# LPC54005 register map
Vendor: nxp.com; File version: 1.0
CPU: CM4 r0p1, little endian, MPU, FPU, VTOR, 3 interrupt priority bits
Registers are 32-bit, read-write, reset 0x0 unless marked. A register's access mark holds for its fields unless they carry their own. Offsets are from the block's base; [hi:lo] are bit positions; {n}, {i} and the like mark numbered series; 'fields as' and 'values as' point back to an identical list.

## SYSCON — LPC5460x System configuration (SYSCON)
Base 0x40000000
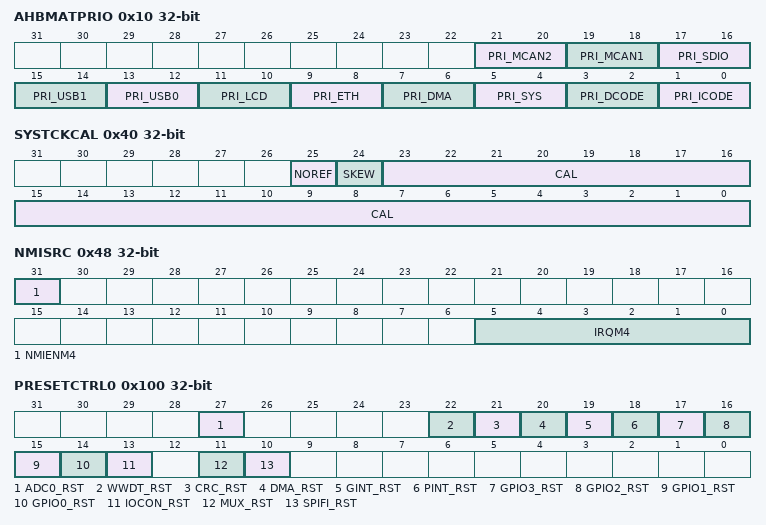
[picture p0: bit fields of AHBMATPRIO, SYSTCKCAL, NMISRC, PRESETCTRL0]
0x10 AHBMATPRIO — AHB multilayer matrix priority control
  [21:20] PRI_MCAN2 — MCAN2 priority.
  [19:18] PRI_MCAN1 — MCAN1 priority.
  [17:16] PRI_SDIO — SDIO priority.
  [15:14] PRI_USB1 — USB1 DMA priority.
  [13:12] PRI_USB0 — USB0 DMA priority.
  [11:10] PRI_LCD — LCD DMA priority.
  [9:8] PRI_ETH — Ethernet DMA priority.
  [7:6] PRI_DMA — DMA controller priority.
  [5:4] PRI_SYS — System bus priority.
  [3:2] PRI_DCODE — D-Code bus priority.
  [1:0] PRI_ICODE — I-Code bus priority.
0x40 SYSTCKCAL — System tick counter calibration
  [25] NOREF — Initial value for the Systick timer.
  [24] SKEW — Initial value for the Systick timer.
  [23:0] CAL — System tick timer calibration value.
0x48 NMISRC — NMI Source Select
  [31] NMIENM4 — Write a 1 to this bit to enable the Non-Maskable Interrupt (NMI) source selected by IRQM4.
  [5:0] IRQM4 — The IRQ number of the interrupt that acts as the Non-Maskable Interrupt (NMI) for the Cortex-M4, if enabled by NMIENM4.
0x4C ASYNCAPBCTRL reset 0x1 — Asynchronous APB Control
  [0] ENABLE — Enables the asynchronous APB bridge and subsystem.
    0=DISABLED (Disabled. Asynchronous APB bridge is disabled.); 1=ENABLED (Enabled. Asynchronous APB bridge is enabled.)
{0xC0+4i} PIOPORCAP[{i}] (i=0..1) ro — POR captured value of port n
  [31:0] PIOPORCAP — State of PIOn_31 through PIOn_0 at power-on reset
{0xD0+4i} PIORESCAP[{i}] (i=0..1) ro — Reset captured value of port n
  [31:0] PIORESCAP — State of PIOn_31 through PIOn_0 for resets other than POR.
0x100 PRESETCTRL0 — Peripheral reset control n
  [27] ADC0_RST — ADC0 reset control. 0 = Clear reset to this function. 1 = Assert reset to this function.
  [22] WWDT_RST — Watchdog timer reset control. 0 = Clear reset to this function. 1 = Assert reset to this function.
  [21] CRC_RST — CRC generator reset control. 0 = Clear reset to this function. 1 = Assert reset to this function.
  [20] DMA_RST — DMA reset control. 0 = Clear reset to this function. 1 = Assert reset to this function.
  [19] GINT_RST — Grouped interrupt (GINT) reset control. 0 = Clear reset to this function. 1 = Assert reset to this function.
  [18] PINT_RST — Pin interrupt (PINT) reset control. 0 = Clear reset to this function. 1 = Assert reset to this function.
  [17] GPIO3_RST — GPIO3 reset control.
  [16] GPIO2_RST — GPIO2 reset control.
  [15] GPIO1_RST — GPIO1 reset control. 0 = Clear reset to this function. 1 = Assert reset to this function.
  [14] GPIO0_RST — GPIO0 reset control. 0 = Clear reset to this function. 1 = Assert reset to this function.
  [13] IOCON_RST — IOCON reset control. 0 = Clear reset to this function. 1 = Assert reset to this function.
  [11] MUX_RST — Input mux reset control. 0 = Clear reset to this function. 1 = Assert reset to this function.
  [10] SPIFI_RST — SPIFI reset control.
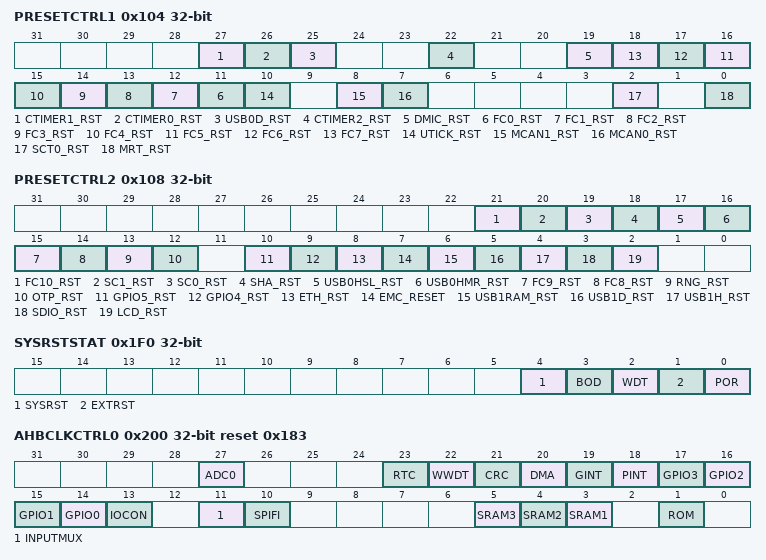
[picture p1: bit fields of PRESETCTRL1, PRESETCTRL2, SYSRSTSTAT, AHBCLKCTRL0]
0x104 PRESETCTRL1 — Peripheral reset control n
  [27] CTIMER1_RST — CTIMER1 reset control. 0 = Clear reset to this function. 1 = Assert reset to this function.
  [26] CTIMER0_RST — CTIMER0 reset control. 0 = Clear reset to this function. 1 = Assert reset to this function.
  [25] USB0D_RST — USB0 reset control. 0 = Clear reset to this function. 1 = Assert reset to this function.
  [22] CTIMER2_RST — CTIMER2 reset control. 0 = Clear reset to this function. 1 = Assert reset to this function
  [19] DMIC_RST — Digital microphone interface reset control. 0 = Clear reset to this function. 1 = Assert reset to this function.
  [n+11] FC{n}_RST (n=0..7) — Flexcomm {n} reset control. 0 = Clear reset to this function. 1 = Assert reset to this function.
  [10] UTICK_RST — Micro-tick Timer reset control. 0 = Clear reset to this function. 1 = Assert reset to this function.
  [8] MCAN1_RST — 0 = Clear reset to this function.
  [7] MCAN0_RST — 0 = Clear reset to this function.
  [2] SCT0_RST — State configurable timer 0 (SCT0) reset control. 0 = Clear reset to this function. 1 = Assert reset to this function.
  [0] MRT_RST — Multi-rate timer (MRT) reset control. 0 = Clear reset to this function. 1 = Assert reset to this function.
0x108 PRESETCTRL2 (reset mask 0xE4FFD85) — Peripheral reset control n
  [21] FC10_RST — Flexcomm 10 reset control.
  [20] SC1_RST — Smart card 1 reset control.
  [19] SC0_RST — Smart card 0 reset control.
  [18] SHA_RST — SHA reset control.
  [17] USB0HSL_RST — USB0 HOST slave reset control.
  [16] USB0HMR_RST — USB0 HOST master reset control.
  [15] FC9_RST — Flexcomm 9 reset control.
  [14] FC8_RST — Flexcomm 8 reset control.
  [13] RNG_RST — RNG reset control.
  [12] OTP_RST — OTP reset control.
  [10] GPIO5_RST — GPIO5 reset control.
  [9] GPIO4_RST — GPIO4 reset control.
  [8] ETH_RST — Ethernet reset control.
  [7] EMC_RESET — EMC reset control.
  [6] USB1RAM_RST — USB1 RAM reset control.
  [5] USB1D_RST — USB1 Device reset control.
  [4] USB1H_RST — USB1 Host reset control.
  [3] SDIO_RST — SDIO reset control.
  [2] LCD_RST — LCD reset control.
{0x120+4i} PRESETCTRLSET[{i}] (i=0..2) wo — Set bits in PRESETCTRLn
  [31:0] RST_SET — Writing ones to this register sets the corresponding bit or bits in the PRESETCTRLn register, if they are implemented. Bits that do not correspond to defined bits in PRESETCTRLn are reserved and only zeroes should be written to them.
{0x140+4i} PRESETCTRLCLR[{i}] (i=0..2) wo — Clear bits in PRESETCTRLn
  [31:0] RST_CLR — Writing ones to this register clears the corresponding bit or bits in the PRESETCTRLn register, if they are implemented. Bits that do not correspond to defined bits in PRESETCTRLn are reserved and only zeroes should be written to them.
0x1F0 SYSRSTSTAT — System reset status register
  [4] SYSRST — Status of the software system reset
    0=NO_SYSTEM_RESET_DETECTED; 1=SYSTEM_RESET_DETECTED (System reset detected. Writing a one clears this reset.)
  [3] BOD — Status of the Brown-out detect reset
    0=NO_BOD_RESET_DETECTED; 1=BOD_RESET_DETECTED (BOD reset detected. Writing a one clears this reset.)
  [2] WDT — Status of the Watchdog reset
    0=NO_WDT_RESET_DETECTED; 1=WDT_RESET_DETECTED (WDT reset detected. Writing a one clears this reset.)
  [1] EXTRST — Status of the external RESET pin. External reset status
    0=NO_RESET_DETECTED (No reset event detected.); 1=RESET_DETECTED (Reset detected. Writing a one clears this reset.)
  [0] POR — POR reset status
    0=NO_POR_DETECTED; 1=POR_DETECTED (POR detected. Writing a one clears this reset.)
0x200 AHBCLKCTRL0 reset 0x183 — AHB Clock control n
  [27] ADC0 — Enables the clock for the ADC0 register interface.
  [23] RTC — Enables the bus clock for the RTC. 0 = Disable; 1 = Enable.
  [22] WWDT — Enables the clock for the Watchdog Timer. 0 = Disable; 1 = Enable.
  [21] CRC — Enables the clock for the CRC engine. 0 = Disable; 1 = Enable.
  [20] DMA — Enables the clock for the DMA controller. 0 = Disable; 1 = Enable.
  [19] GINT — Enables the clock for the grouped pin interrupt block. 0 = Disable; 1 = Enable.
  [18] PINT — Enables the clock for the pin interrupt block.0 = Disable; 1 = Enable.
  [17] GPIO3 — Enables the clock for the GPIO3 port registers.
  [16] GPIO2 — Enables the clock for the GPIO2 port registers.
  [15] GPIO1 — Enables the clock for the GPIO1 port registers. 0 = Disable; 1 = Enable.
  [14] GPIO0 — Enables the clock for the GPIO0 port registers. 0 = Disable; 1 = Enable.
  [13] IOCON — Enables the clock for the IOCON block. 0 = Disable; 1 = Enable.
  [11] INPUTMUX — Enables the clock for the input muxes. 0 = Disable; 1 = Enable.
  [10] SPIFI — Enables the clock for the SPIFI. 0 = Disable; 1 = Enable.
  [5] SRAM3 — Enables the clock for SRAM3.
  [4] SRAM2 — Enables the clock for SRAM2. 0 = Disable; 1 = Enable.
  [3] SRAM1 — Enables the clock for SRAM1. 0 = Disable; 1 = Enable.
  [1] ROM — Enables the clock for the Boot ROM. 0 = Disable; 1 = Enable.
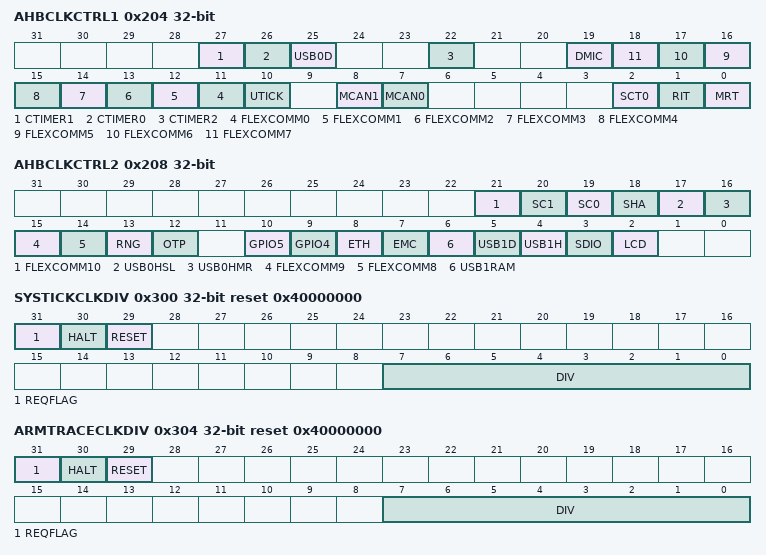
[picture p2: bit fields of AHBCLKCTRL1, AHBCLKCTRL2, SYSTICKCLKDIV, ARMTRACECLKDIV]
0x204 AHBCLKCTRL1 — AHB Clock control n
  [27] CTIMER1 — Enables the clock for timer CTIMER1. 0 = Disable; 1 = Enable.
  [26] CTIMER0 — Enables the clock for timer CTIMER0. 0 = Disable; 1 = Enable.
  [25] USB0D — Enables the clock for the USB0 device interface. 0 = Disable; 1 = Enable.
  [22] CTIMER2 — Enables the clock for CTIMER 2. 0 = Disable; 1 = Enable.
  [19] DMIC — Enables the clock for the digital microphone interface. 0 = Disable; 1 = Enable.
  [n+11] FLEXCOMM{n} (n=0..7) — Enables the clock for Flexcomm {n}. 0 = Disable; 1 = Enable.
  [10] UTICK — Enables the clock for the Micro-tick Timer. 0 = Disable; 1 = Enable.
  [8] MCAN1 — Enables the clock for MCAN1.
  [7] MCAN0 — Enables the clock for MCAN0.
  [2] SCT0 — Enables the clock for SCT0.
  [1] RIT — Enables the clock for the Repetitive Interrupt Timer.
  [0] MRT — Enables the clock for the Multi-Rate Timer.
0x208 AHBCLKCTRL2 (reset mask 0xE4FFD87) — AHB Clock control n
  [21] FLEXCOMM10 — Enables the clock for the Flexcomm10 interface.
  [20] SC1 — Enables the clock for the Smart card1 interface.
  [19] SC0 — Enables the clock for the Smart card0 interface.
  [18] SHA — Enables the clock for the SHA interface.
  [17] USB0HSL — Enables the clock for the USB host slave interface.
  [16] USB0HMR — Enables the clock for the USB host master interface.
  [15] FLEXCOMM9 — Enables the clock for the Flexcomm9 interface.
  [14] FLEXCOMM8 — Enables the clock for the Flexcomm8 interface.
  [13] RNG — Enables the clock for the RNG interface.
  [12] OTP — Enables the clock for the OTP interface.
  [10] GPIO5 — Enables the clock for the GPIO5 interface.
  [9] GPIO4 — Enables the clock for the GPIO4 interface.
  [8] ETH — Enables the clock for the ethernet interface.
  [7] EMC — Enables the clock for the EMC interface.
  [6] USB1RAM — Enables the clock for the USB1 RAM interface.
  [5] USB1D — Enables the clock for the USB1 device interface.
  [4] USB1H — Enables the clock for the USB1 host interface.
  [3] SDIO — Enables the clock for the SDIO interface.
  [2] LCD — Enables the clock for the LCD interface.
{0x220+4i} AHBCLKCTRLSET[{i}] (i=0..2) wo — Set bits in AHBCLKCTRLn
  [31:0] CLK_SET — Writing ones to this register sets the corresponding bit or bits in the AHBCLKCTRLn register, if they are implemented. Bits that do not correspond to defined bits in AHBCLKCTRLn are reserved and only zeroes should be written to them.
{0x240+4i} AHBCLKCTRLCLR[{i}] (i=0..2) wo — Clear bits in AHBCLKCTRLn
  [31:0] CLK_CLR — Writing ones to this register clears the corresponding bit or bits in the AHBCLKCTRLn register, if they are implemented. Bits that do not correspond to defined bits in AHBCLKCTRLn are reserved and only zeroes should be written to them.
0x27C STICKCLKSEL — Systick timer clock source selection
  [2:0] SEL
    0=MAIN_CLOCK (Main clock (main_clk)); 1=WATCHDOG_OSCILLATOR (Watchdog oscillator (wdt_clk)); 2=RTC_OSC_OUTPUT (RTC oscillator 32 kHz output (32k_clk)); 3=FRO_12_MHZ (FRO 12 MHz (fro_12m)); 7=NONE (None, this may be selected to reduce power when no output is needed.)
0x280 MAINCLKSELA — Main clock source select A
  [1:0] SEL — Clock source for main clock source selector A
    0=FRO_12_MHZ (FRO 12 MHz (fro_12m)); 1=CLKIN (CLKIN (clk_in)); 2=WATCHDOG_OSCILLATOR (Watchdog oscillator (wdt_clk)); 3=FRO_HF (FRO 96 or 48 MHz (fro_hf))
0x284 MAINCLKSELB — Main clock source select B
  [1:0] SEL — Clock source for main clock source selector B. Selects the clock source for the main clock.
    0=MAINCLKSELA (MAINCLKSELA. Use the clock source selected in MAINCLKSELA register.); 2=SYSTEM_PLL_OUTPUT (System PLL output (pll_clk)); 3=RTC_OSC_OUTPUT (RTC oscillator 32 kHz output (32k_clk))
0x288 CLKOUTSELA reset 0x7 — CLKOUT clock source select A
  [2:0] SEL — CLKOUT clock source selection
    0=MAIN_CLOCK (Main clock (main_clk)); 1=CLKIN (CLKIN (clk_in)); 2=WATCHDOG_OSCILLATOR (Watchdog oscillator (wdt_clk)); 3=FRO_HF (FRO 96 or 48 MHz (fro_hf)); 4=SYSTEM_PLL_OUTPUT (PLL output (pll_clk)); 5=USB_PLL_CLOCK (USB PLL clock (usb_pll_clk)); 6=AUDIO_PLL_OUTPUT (Audio PLL clock (audio_pll_clk)); 7=RTC_OSC_OUTPUT (RTC oscillator 32 kHz output (32k_clk))
0x290 SYSPLLCLKSEL — PLL clock source select
  [2:0] SEL — System PLL clock source selection.
    0=FRO_12_MHZ (FRO 12 MHz (fro_12m)); 1=CLKIN (CLKIN (clk_in)); 3=RTC_OSC_OUTPUT (RTC oscillator 32 kHz output (32k_clk)); 7=NONE (None, this may be selected in order to reduce power when no output is needed.)
0x298 AUDPLLCLKSEL — Audio PLL clock source select
  [2:0] SEL — Audio PLL clock source selection.
    0=FRO_12_MHZ (FRO 12 MHz (fro_12m)); 1=CLKIN (CLKIN (clk_in)); 7=NONE (None, this may be selected in order to reduce power when no output is needed.)
0x2A0 SPIFICLKSEL reset 0x7 — SPIFI clock source select
  [2:0] SEL — System PLL clock source selection
    0=MAIN_CLOCK (Main clock (main_clk)); 1=SYSTEM_PLL_OUTPUT (System PLL output (pll_clk)); 2=USB_PLL_OUTPUT (USB PLL clock (usb_pll_clk)); 3=FRO_HF (FRO 96 or 48 MHz (fro_hf)); 4=AUDIO_PLL_OUTPUT (Audio PLL clock (audio_pll_clk)); 7=NONE (None, this may be selected in order to reduce power when no output is needed.)
0x2A4 ADCCLKSEL reset 0x7 — ADC clock source select
  [2:0] SEL — ADC clock source selection
    0=FRO_HF (FRO 96 or 48 MHz (fro_hf)); 1=SYSTEM_PLL_OUTPUT (System PLL output (pll_clk)); 2=USB_PLL_CLOCK (USB PLL clock (usb_pll_clk)); 3=AUDIO_PLL_CLOCK (Audio PLL clock (audio_pll_clk)); 7=NONE (None, this may be selected in order to reduce power when no output is needed.)
0x2A8 USB0CLKSEL reset 0x7 — USB0 clock source select
  [2:0] SEL — USB0 device clock source selection.
    0=FRO_HF (FRO 96 or 48 MHz (fro_hf)); 1=SYSTEM_PLL_OUTPUT (System PLL output (pll_clk)); 2=USB_PLL_CLOCK (USB PLL clock (usb_pll_clk)); 7=NONE (None, this may be selected in order to reduce power when no output is needed.)
0x2AC USB1CLKSEL reset 0x7 — USB1 clock source select
  [2:0] SEL — USB1 PHY clock source selection.
    0=MAIN_CLOCK (Main clock (main_clk)); 1=SYSTEM_PLL_OUTPUT (System PLL output (pll_clk)); 2=USB_PLL_CLOCK (USB PLL clock (usb_pll_clk)); 7=NONE (None, this may be selected in order to reduce power when no output is needed.)
{0x2B0+4i} FCLKSEL[{i}] (i=0..9) reset 0x7 — Flexcomm clock source select
  [2:0] SEL — Flexcomm clock source selection. One per Flexcomm.
    0=FRO_12_MHZ (FRO 12 MHz (fro_12m)); 1=FRO_HF_DIV (FRO HF DIV (fro_hf_div)); 2=AUDIO_PLL_OUTPUT (Audio PLL clock (audio_pll_clk)); 3=MCLK_INPUT (MCLK pin input, when selected in IOCON (mclk_in)); 4=FRG_CLOCK_OUTPUT (FRG clock, the output of the fractional rate generator (frg_clk)); 7=NONE (None, this may be selected in order to reduce power when no output is needed.)
0x2D8 FCLKSEL10 reset 0x7 — Flexcomm 10 clock source select
  [2:0] SEL — Flexcomm clock source selection. One per Flexcomm.
    0=MAIN_CLOCK (Main clock (main_clk)); 1=SYSTEM_PLL_OUTPUT (System PLL output (pll_clk)); 2=USB_PLL_CLOCK (USB PLL clock (usb_pll_clk)); 3=FRO_HF (FRO 96 or 48 MHz (fro_hf)); 4=AUDIO_PLL_OUTPUT (Audio PLL clock (audio_pll_clk)); 7=NONE (None, this may be selected in order to reduce power when no output is needed.)
0x2E0 MCLKCLKSEL reset 0x7 — MCLK clock source select
  [2:0] SEL — MCLK source select. This may be used by Flexcomms that support I2S, and/or by the digital microphone subsystem.
    0=FRO_HF_DIV (FRO HF DIV (fro_hf_div)); 1=AUDIO_PLL_OUTPUT (Audio PLL clock (audio_pll_clk)); 7=NONE (None, this may be selected in order to reduce power when no output is needed.)
0x2E8 FRGCLKSEL reset 0x7 — Fractional Rate Generator clock source select
  [2:0] SEL — Fractional Rate Generator clock source select.
    0=MAIN_CLOCK (Main clock (main_clk)); 1=SYSTEM_PLL_OUTPUT (System PLL output (pll_clk)); 2=FRO_12_MHZ (FRO 12 MHz (fro_12m)); 3=FRO_HF (FRO 96 or 48 MHz (fro_hf)); 7=NONE (None, this may be selected in order to reduce power when no output is needed.)
0x2EC DMICCLKSEL reset 0x7 — Digital microphone (DMIC) subsystem clock select
  [2:0] SEL — DMIC (audio subsystem) clock source select.
    0=FRO_12_MHZ (FRO 12 MHz (fro_12m)); 1=FRO_HF_DIV (FRO HF DIV (fro_hf_div)); 2=AUDIO_PLL_OUTPUT (Audio PLL clock (audio_pll_clk)); 3=MCLK_INPUT (MCLK pin input, when selected in IOCON (mclk_in)); 4=MAIN_CLOCK (Main clock (main_clk)); 5=WATCHDOG_OSCILLATOR (Watchdog oscillator (wdt_clk)); 7=NONE (None, this may be selected in order to reduce power when no output is needed.)
0x2F0 SCTCLKSEL reset 0x7 — SCTimer/PWM clock source select
  [2:0] SEL — SCT clock source select.
    0=MAIN_CLOCK (Main clock (main_clk)); 1=SYSTEM_PLL_OUTPUT (System PLL output (pll_clk)); 2=FRO_HF (FRO 96 or 48 MHz (fro_hf)); 3=AUDIO_PLL_OUTPUT (Audio PLL clock (audio_pll_clk)); 7=NONE (None, this may be selected in order to reduce power when no output is needed.)
0x2F4 LCDCLKSEL reset 0x3 — LCD clock source select
  [1:0] SEL — LCD clock source select.
    0=MAIN_CLOCK (Main clock (main_clk)); 1=LCDCLKIN (LCDCLKIN (LCDCLK_EXT)); 2=FRO_HF (FRO 96 or 48 MHz (fro_hf)); 3=NONE (None, this may be selected in order to reduce power when no output is needed.)
0x2F8 SDIOCLKSEL reset 0x7 — SDIO clock source select
  [2:0] SEL — SDIO clock source select.
    values as FCLKSEL10.SEL
0x300 SYSTICKCLKDIV reset 0x40000000 — SYSTICK clock divider
  [31] REQFLAG — Divider status flag.
  [30] HALT — Halts the divider counter.
  [29] RESET — Resets the divider counter. Can be used to make sure a new divider value is used right away rather than completing the previous count.
  [7:0] DIV — Clock divider value. 0: Divide by 1 up to 255: Divide by 256.
0x304 ARMTRACECLKDIV reset 0x40000000 — ARM Trace clock divider
  [31] REQFLAG — Divider status flag.
  [30] HALT — Halts the divider counter.
  [29] RESET — Resets the divider counter.
  [7:0] DIV — Clock divider value.
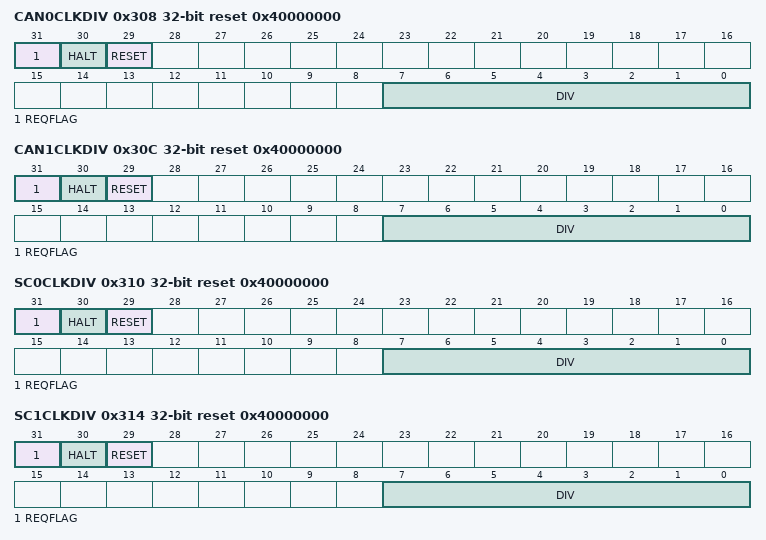
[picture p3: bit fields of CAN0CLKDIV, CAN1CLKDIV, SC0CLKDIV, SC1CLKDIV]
0x308 CAN0CLKDIV reset 0x40000000 — MCAN0 clock divider
  fields as ARMTRACECLKDIV
0x30C CAN1CLKDIV reset 0x40000000 — MCAN1 clock divider
  fields as SYSTICKCLKDIV
0x310 SC0CLKDIV reset 0x40000000 — Smartcard0 clock divider
  fields as ARMTRACECLKDIV
0x314 SC1CLKDIV reset 0x40000000 — Smartcard1 clock divider
  fields as ARMTRACECLKDIV
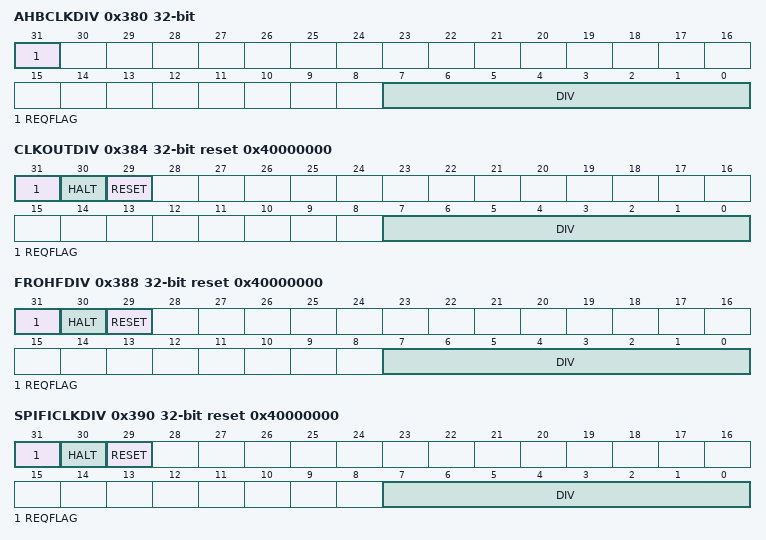
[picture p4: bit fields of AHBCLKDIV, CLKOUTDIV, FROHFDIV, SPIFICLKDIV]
0x380 AHBCLKDIV (reset mask 0x600000FF) — AHB clock divider
  [31] REQFLAG — Divider status flag.
  [7:0] DIV — Clock divider value. 0: Divide by 1 up to 255: Divide by 256.
0x384 CLKOUTDIV reset 0x40000000 (reset mask 0x600000FF) — CLKOUT clock divider
  [31] REQFLAG — Divider status flag.
  [30] HALT — Halts the divider counter. The intent is to allow the divider clock source to be changed without the risk of a glitch at the output.
  [29] RESET — Resets the divider counter. Can be used to make sure a new divider value is used right away rather than completing the previous count.
  [7:0] DIV — Clock divider value. 0: Divide by 1 up to 255: Divide by 256.
0x388 FROHFDIV reset 0x40000000 — FROHF clock divider
  fields as ARMTRACECLKDIV
0x390 SPIFICLKDIV reset 0x40000000 — SPIFI clock divider
  [31] REQFLAG — Divider status flag.
  [30] HALT — Halts the divider counter. The intent is to allow the divider clock source to be changed without the risk of a glitch at the output.
  [29] RESET — Resets the divider counter. Can be used to make sure a new divider value is used right away rather than completing the previous count.
  [7:0] DIV — Clock divider value.
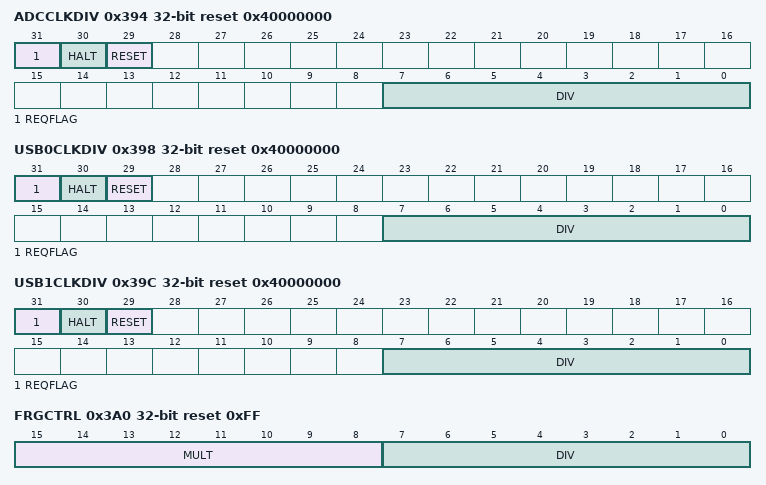
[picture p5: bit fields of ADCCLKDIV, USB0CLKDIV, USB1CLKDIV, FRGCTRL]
0x394 ADCCLKDIV reset 0x40000000 — ADC clock divider
  fields as ARMTRACECLKDIV
0x398 USB0CLKDIV reset 0x40000000 — USB0 clock divider
  fields as ARMTRACECLKDIV
0x39C USB1CLKDIV reset 0x40000000 — USB1 clock divider
  fields as ARMTRACECLKDIV
0x3A0 FRGCTRL reset 0xFF — Fractional rate divider
  [15:8] MULT — Numerator of the fractional divider. MULT is equal to the programmed value.
  [7:0] DIV — Denominator of the fractional divider. DIV is equal to the programmed value +1. Always set to 0xFF to use with the fractional baud rate generator.
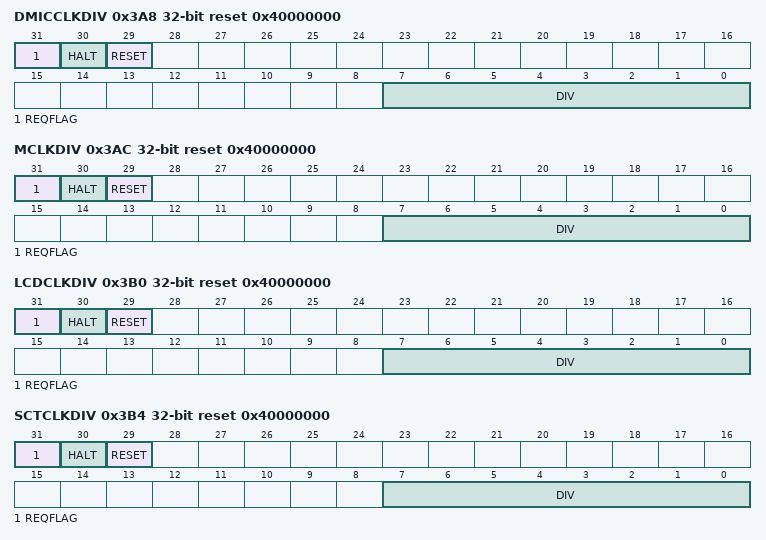
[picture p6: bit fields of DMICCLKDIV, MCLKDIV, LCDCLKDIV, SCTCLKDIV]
0x3A8 DMICCLKDIV reset 0x40000000 (reset mask 0x600000FF) — DMIC clock divider
  fields as CLKOUTDIV
0x3AC MCLKDIV reset 0x40000000 — I2S MCLK clock divider
  [31] REQFLAG — Divider status flag.
  [30] HALT — Halts the divider counter.
  [29] RESET — Resets the divider counter.
  [7:0] DIV — Clock divider value. 0: Divide by 1 up to 255: Divide by 256.
0x3B0 LCDCLKDIV reset 0x40000000 — LCD clock divider
  fields as ARMTRACECLKDIV
0x3B4 SCTCLKDIV reset 0x40000000 — SCT/PWM clock divider
  fields as ARMTRACECLKDIV
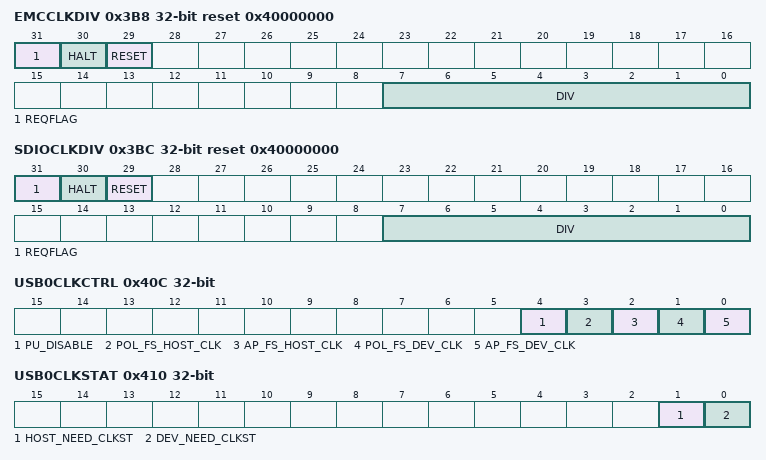
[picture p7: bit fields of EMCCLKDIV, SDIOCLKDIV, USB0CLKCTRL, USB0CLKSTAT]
0x3B8 EMCCLKDIV reset 0x40000000 — EMC clock divider
  fields as ARMTRACECLKDIV
0x3BC SDIOCLKDIV reset 0x40000000 — SDIO clock divider
  fields as ARMTRACECLKDIV
0x40C USB0CLKCTRL — USB0 clock control
  [4] PU_DISABLE — Internal pull-up disable control.
  [3] POL_FS_HOST_CLK — USB0 Host USB0_NEEDCLK polarity for triggering the USB0 wake-up interrupt.
  [2] AP_FS_HOST_CLK — USB0 Host USB0_NEEDCLK signal control.
  [1] POL_FS_DEV_CLK — USB0 Device USB0_NEEDCLK polarity for triggering the USB0 wake-up interrupt.
  [0] AP_FS_DEV_CLK — USB0 Device USB0_NEEDCLK signal control.
0x410 USB0CLKSTAT — USB0 clock status
  [1] HOST_NEED_CLKST — USB0 Host USB0_NEEDCLK signal status.
  [0] DEV_NEED_CLKST — USB0 Device USB0_NEEDCLK signal status.
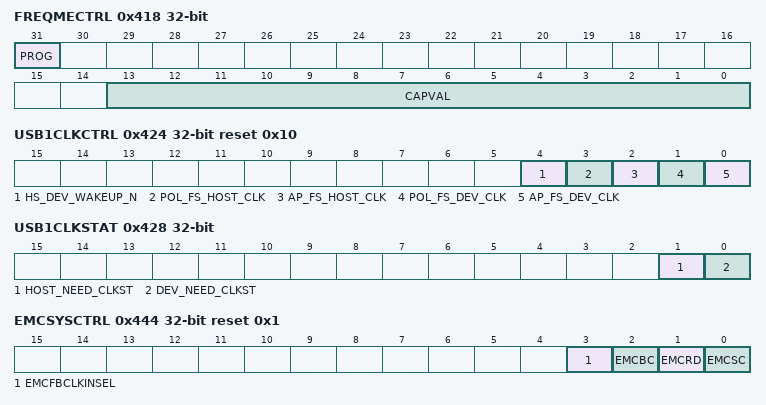
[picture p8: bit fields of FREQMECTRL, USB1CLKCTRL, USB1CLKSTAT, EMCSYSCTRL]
0x418 FREQMECTRL — Frequency measure register
  [31] PROG — Set this bit to one to initiate a frequency measurement cycle. Hardware clears this bit when the measurement cycle has completed and there is valid capture data in the CAPVAL field (bits 13:0).
  [13:0] CAPVAL — Stores the capture result which is used to calculate the frequency of the target clock. This field is read-only.
0x420 MCLKIO — MCLK input/output control
  [0] DIR — MCLK direction control.
0x424 USB1CLKCTRL reset 0x10 — USB1 clock control
  [4] HS_DEV_WAKEUP_N — External user wake-up signal for device mode; asserting this signal (active low) will result in exiting the low power mode; input to asynchronous control logic.
  [3] POL_FS_HOST_CLK — USB1 Host need_clock polarity for triggering the USB1 wake-up interrupt.
  [2] AP_FS_HOST_CLK — USB1 Host need_clock signal control.
  [1] POL_FS_DEV_CLK — USB1 Device need_clock polarity for triggering the USB1 wake-up interrupt.
  [0] AP_FS_DEV_CLK — USB1 Device need_clock signal control.
0x428 USB1CLKSTAT — USB1 clock status
  [1] HOST_NEED_CLKST — USB1 Device host USB1_NEEDCLK signal status.
  [0] DEV_NEED_CLKST — USB1 Device USB1_NEEDCLK signal status.
0x444 EMCSYSCTRL reset 0x1 — EMC system control
  [3] EMCFBCLKINSEL — External Memory Controller clock select.
  [2] EMCBC — External Memory Controller burst control.
  [1] EMCRD — EMC Reset Disable.
  [0] EMCSC — EMC Shift Control.
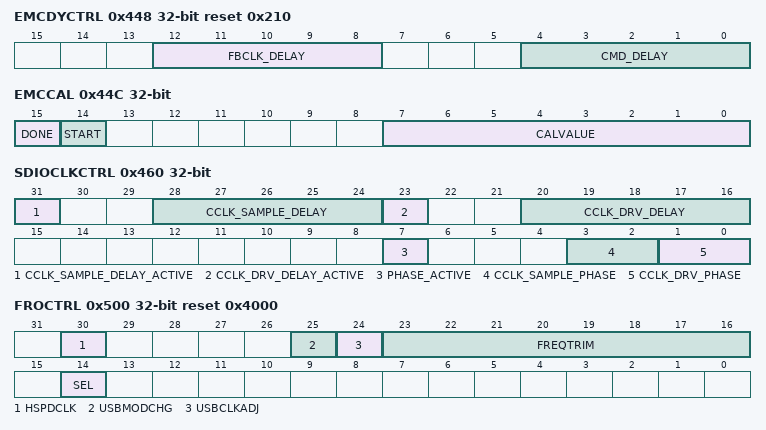
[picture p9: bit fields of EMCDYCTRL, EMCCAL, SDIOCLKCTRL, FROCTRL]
0x448 EMCDYCTRL reset 0x210 — EMC clock delay control
  [12:8] FBCLK_DELAY — Programmable delay value for the feedback clock that controls input data sampling.
  [4:0] CMD_DELAY — Programmable delay value for EMC outputs in command delayed mode.
0x44C EMCCAL — EMC delay chain calibration control
  [15] DONE — Measurement completion flag.
  [14] START — Start control bit for the EMC calibration counter.
  [7:0] CALVALUE — Returns the count of the approximately 50 MHz ring oscillator that occur during 32 clocks of the FRO 12 MHz.
0x450 ETHPHYSEL — Ethernet PHY Selection
  [2] PHY_SEL — PHY interface select.
0x454 ETHSBDCTRL — Ethernet SBD flow control
  [1:0] SBD_CTRL — Sideband Flow Control.
0x460 SDIOCLKCTRL — SDIO CCLKIN phase and delay control
  [31] CCLK_SAMPLE_DELAY_ACTIVE — Enables sample delay, as controlled by the CCLK_SAMPLE_DELAY field.
  [28:24] CCLK_SAMPLE_DELAY — Programmable delay value by which cclk_in_sample is delayed with regard to cclk_in.
  [23] CCLK_DRV_DELAY_ACTIVE — Enables drive delay, as controlled by the CCLK_DRV_DELAY field.
  [20:16] CCLK_DRV_DELAY — Programmable delay value by which cclk_in_drv is delayed with regard to cclk_in.
  [7] PHASE_ACTIVE — sdio_clk by 2, before feeding into ccl_in, cclk_in_sample, and cclk_in_drv.
  [3:2] CCLK_SAMPLE_PHASE — Programmable delay value by which cclk_in_sample is delayed with regard to cclk_in.
  [1:0] CCLK_DRV_PHASE — Programmable delay value by which cclk_in_drv is phase-shifted with regard to cclk_in.
0x500 FROCTRL reset 0x4000 — FRO oscillator control
  [30] HSPDCLK — High speed clock enable.
  [25] USBMODCHG — USB Mode value Change flag.
  [24] USBCLKADJ — USB clock adjust mode.
  [23:16] FREQTRIM — Frequency trim.
  [14] SEL — Select the FRO HF output frequency.
0x504 SYSOSCCTRL — System oscillator control
  [1] FREQRANGE — Determines frequency range for system oscillator.
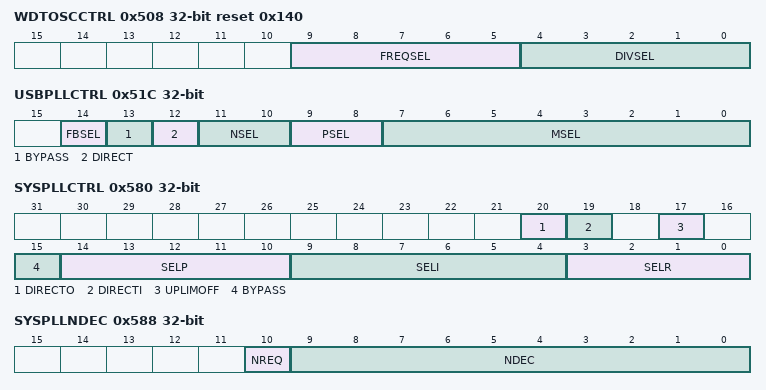
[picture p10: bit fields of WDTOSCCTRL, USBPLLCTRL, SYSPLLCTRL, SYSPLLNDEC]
0x508 WDTOSCCTRL reset 0x140 — Watchdog oscillator control
  [9:5] FREQSEL — Frequency select.
  [4:0] DIVSEL — Divider select.
0x50C RTCOSCCTRL reset 0x1 — RTC oscillator 32 kHz output control
  [0] EN — RTC 32 kHz clock enable.
0x51C USBPLLCTRL reset not defined — USB PLL control
  [14] FBSEL — Feedback divider input clock control.
  [13] BYPASS — Input clock bypass control.
    0=DISABLED (CCO clock is sent to post dividers..); 1=ENABLED (PLL input clock is sent to post dividers..)
  [12] DIRECT — Direct CCO clock output control.
    0=DISABLED (CCO Clock signal goes through post divider.); 1=ENABLED (CCO Clock signal goes directly to output(s)..)
  [11:10] NSEL — PLL feedback Divider value.
  [9:8] PSEL — PLL Divider value.
  [7:0] MSEL — PLL feedback Divider value.
0x520 USBPLLSTAT reset not defined — USB PLL status
  [0] LOCK — USBPLL lock indicator.
0x580 SYSPLLCTRL — System PLL control
  [20] DIRECTO — PLL0 direct output enable.
    0=DISABLED (Disabled. The PLL output divider (P divider) is used to create the PLL output.); 1=ENABLED (Enabled. The PLL output divider (P divider) is bypassed, the PLL CCO output is used as the PLL output.)
  [19] DIRECTI — PLL0 direct input enable.
  [17] UPLIMOFF — Disable upper frequency limiter.
  [15] BYPASS — PLL bypass control.
    0=DISABLED (Bypass disabled. PLL CCO is sent to the PLL post-dividers.); 1=ENABLED (Bypass enabled. PLL input clock is sent directly to the PLL output (default).)
  [14:10] SELP — Bandwidth select P value.
  [9:4] SELI — Bandwidth select I value.
  [3:0] SELR — Bandwidth select R value.
0x584 SYSPLLSTAT reset not defined — PLL status
  [0] LOCK — PLL lock indicator.
0x588 SYSPLLNDEC reset not defined — PLL N divider
  [10] NREQ — NDEC reload request.
  [9:0] NDEC — Decoded N-divider coefficient value.
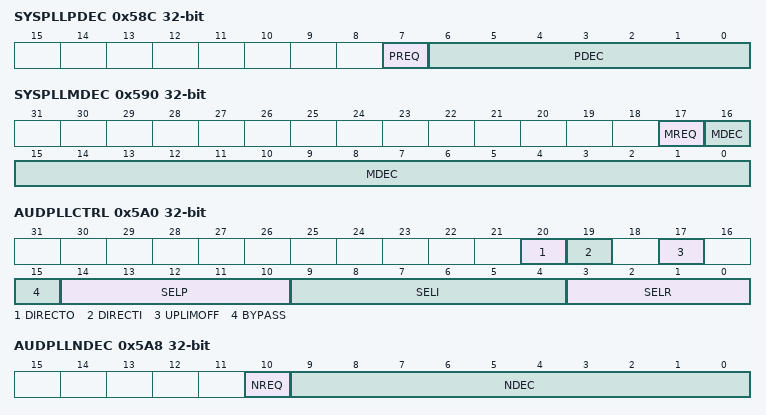
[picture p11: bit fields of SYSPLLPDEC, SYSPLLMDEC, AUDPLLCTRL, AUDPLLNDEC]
0x58C SYSPLLPDEC reset not defined — PLL P divider
  [7] PREQ
  [6:0] PDEC — Decoded P-divider coefficient value.
0x590 SYSPLLMDEC reset not defined — System PLL M divider
  [17] MREQ — MDEC reload request.
  [16:0] MDEC — Decoded M-divider coefficient value.
0x5A0 AUDPLLCTRL reset not defined — Audio PLL control
  [20] DIRECTO — PLL direct output enable
    values as SYSPLLCTRL.DIRECTO
  [19] DIRECTI — PLL direct input enable.
  [17] UPLIMOFF — Disable upper frequency limiter.
  [15] BYPASS — PLL bypass control.
    values as SYSPLLCTRL.BYPASS
  [14:10] SELP
  [9:4] SELI — Bandwidth select I value.
  [3:0] SELR — Bandwidth select R value.
0x5A4 AUDPLLSTAT reset not defined — Audio PLL status
  [0] LOCK — PLL lock indicator.
0x5A8 AUDPLLNDEC reset not defined — Audio PLL N divider
  fields as SYSPLLNDEC
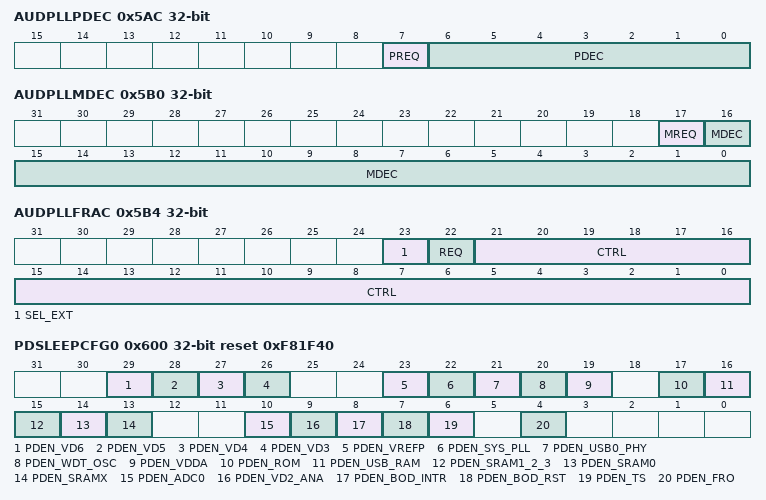
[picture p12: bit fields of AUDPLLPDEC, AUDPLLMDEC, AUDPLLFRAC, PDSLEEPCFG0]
0x5AC AUDPLLPDEC reset not defined — Audio PLL P divider
  [7] PREQ — PDEC reload request.
  [6:0] PDEC — Decoded P-divider coefficient value.
0x5B0 AUDPLLMDEC reset not defined — Audio PLL M divider
  fields as SYSPLLMDEC
0x5B4 AUDPLLFRAC reset not defined — Audio PLL fractional divider control
  [23] SEL_EXT — Select fractional divider.
  [22] REQ — Writing 1 to REQ signal loads CTRL value into fractional wrapper modulator.
  [21:0] CTRL — PLL fractional divider control word
0x600 PDSLEEPCFG0 reset 0xF81F40 (reset mask 0xFBFFD0) — Sleep configuration register
  [29] PDEN_VD6 — Power control for EEPROM.
  [28] PDEN_VD5 — Power control both USB0 PHY and USB1 PHY.
  [27] PDEN_VD4 — Power control for all SRAMs and ROM.
  [26] PDEN_VD3 — Power control for all PLLs.
  [23] PDEN_VREFP — VREFP to the ADC must be enabled for the ADC to work (also enable/disable bit 9, 10, and 19).
  [22] PDEN_SYS_PLL — System PLL (PLL0) power (also enable/disable bit 26).
  [21] PDEN_USB0_PHY — USB0 PHY power (also enable/disable bit 28).
  [20] PDEN_WDT_OSC — Watchdog oscillator.
  [19] PDEN_VDDA — Vdda to the ADC, must be enabled for the ADC to work (also enable/disable bit 9, 10, and 23).
  [17] PDEN_ROM — ROM (also enable/disable bit 27).
  [16] PDEN_USB_RAM — PDEN_USB_SRAM controls USB_RAM (also enable/disable bit 27).
  [15] PDEN_SRAM1_2_3 — PDEN_SRAM1_2_3 controls SRAM1, SRAM2, and SRAM3 (also enable/disable bit 27).
  [14] PDEN_SRAM0 — PDEN_SRAM0 controls SRAM0 (also enable/disable bit 27).
  [13] PDEN_SRAMX — PDEN_SRAMX controls SRAMX (also enable/disable bit 27).
  [10] PDEN_ADC0 — ADC power.
  [9] PDEN_VD2_ANA — Analog supply for System Oscillator (also enable/disable bit 3 in PDRUNCFG1 register), Temperature Sensor (also, enable/disable bit 6), ADC (also, enable/disable bits 10, 19, and 23).
  [8] PDEN_BOD_INTR — Brown-out Detect interrupt.
  [7] PDEN_BOD_RST — Brown-out Detect reset.
  [6] PDEN_TS — Temp sensor.
  [4] PDEN_FRO — FRO oscillator.
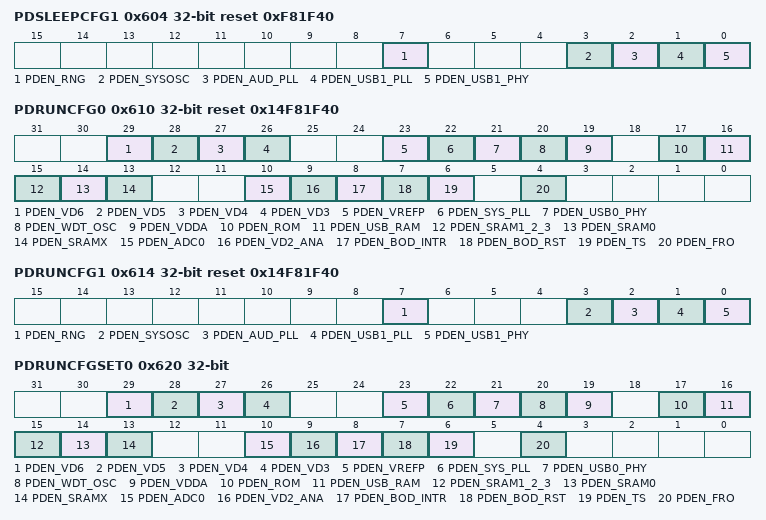
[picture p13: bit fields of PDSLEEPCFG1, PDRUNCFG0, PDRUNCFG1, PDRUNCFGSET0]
0x604 PDSLEEPCFG1 reset 0xF81F40 (reset mask 0xFBFFD0) — Sleep configuration register
  [7] PDEN_RNG — Random Number Generator Power.
  [3] PDEN_SYSOSC — System Oscillator Power (also, enable/disable bit 9 in PDRUNCFG0 register).
  [2] PDEN_AUD_PLL — Audio PLL (PLL2) power and fractional divider (also, enable/disable bit 26 in PDRUNCFG0 register).
  [1] PDEN_USB1_PLL — USB PLL (PLL1) power (also, enable/disable bit 26 in PDRUNCFG0 register).
  [0] PDEN_USB1_PHY — USB1 high speed PHY (also, enable/disable bit 28 in PDRUNCFG0 register).
0x610 PDRUNCFG0 reset 0x14F81F40 — Power configuration register
  [29] PDEN_VD6 — Power control for OTP and SRAMX from address 0x00010000 to 0x0002FFFF.
  [28] PDEN_VD5 — Power control both USB0 PHY and USB1 PHY.
  [27] PDEN_VD4 — Power control for all SRAMs and ROM.
  [26] PDEN_VD3 — Power control for all PLLs.
  [23] PDEN_VREFP — VREFP to the ADC must be enabled for the ADC to work (also enable/disable bit 9, 10, and 19).
  [22] PDEN_SYS_PLL — System PLL (PLL0) power (also enable/disable bit 26).
  [21] PDEN_USB0_PHY — USB0 PHY power (also enable/disable bit 28).
  [20] PDEN_WDT_OSC — Watchdog oscillator.
  [19] PDEN_VDDA — Vdda to the ADC, must be enabled for the ADC to work (also enable/disable bit 9, 10, and 23).
  [17] PDEN_ROM — ROM (also enable/disable bit 27).
  [16] PDEN_USB_RAM — PDEN_USB_SRAM controls USB_RAM (also enable/disable bit 27).
  [15] PDEN_SRAM1_2_3 — PDEN_SRAM1_2_3 controls SRAM1, SRAM2, and SRAM3 (also enable/disable bit 27).
  [14] PDEN_SRAM0 — PDEN_SRAM0 controls SRAM0 (also enable/disable bit 27).
  [13] PDEN_SRAMX — PPDEN_SRAMX controls only SRAMX address 0x0 to 0x0000FFFF.Bit 29 (PDEN_VD6) controls SRAMX address 0x00010000 to 0x0002FFFF..
  [10] PDEN_ADC0 — ADC power.
  [9] PDEN_VD2_ANA — Analog supply for System Oscillator (also enable/disable bit 3 in PDRUNCFG1 register), Temperature Sensor (also, enable/disable bit 6), ADC (also, enable/disable bits 10, 19, and 23).
  [8] PDEN_BOD_INTR — Brown-out Detect interrupt.
  [7] PDEN_BOD_RST — Brown-out Detect reset.
  [6] PDEN_TS — Temp sensor.
  [4] PDEN_FRO — FRO oscillator.
0x614 PDRUNCFG1 reset 0x14F81F40 (reset mask 0x3CFBFFD0) — Power configuration register
  fields as PDSLEEPCFG1
0x620 PDRUNCFGSET0 — Power configuration set register
  fields as PDSLEEPCFG0
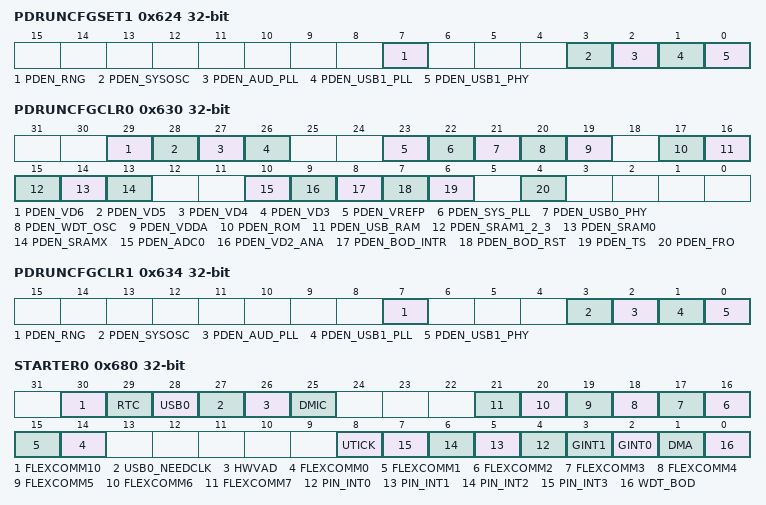
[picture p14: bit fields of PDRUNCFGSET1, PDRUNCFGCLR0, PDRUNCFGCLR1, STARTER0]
0x624 PDRUNCFGSET1 — Power configuration set register
  fields as PDSLEEPCFG1
0x630 PDRUNCFGCLR0 — Power configuration clear register
  fields as PDSLEEPCFG0
0x634 PDRUNCFGCLR1 — Power configuration clear register
  fields as PDSLEEPCFG1
0x680 STARTER0 (reset mask 0x3FFFFFFF) — Start logic 0 wake-up enable register
  [30] FLEXCOMM10 — Flexcomm10 peripheral interrupt wake-up.
  [29] RTC — RTC interrupt alarm and wake-up timer.
  [28] USB0 — USB function interrupt wake-up.
  [27] USB0_NEEDCLK — USB activity interrupt wake-up.
  [26] HWVAD — Hardware voice activity detect interrupt wake-up.
  [25] DMIC — Digital microphone interrupt wake-up.
  [n+14] FLEXCOMM{n} (n=0..7) — Flexcomm{n} peripheral interrupt wake-up.
  [8] UTICK — Micro-tick Timer wake-up.
  [n+4] PIN_INT{n} (n=0..3) — GPIO pin interrupt {n} wake-up.
  [3] GINT1 — Group interrupt 1 wake-up.
  [2] GINT0 — Group interrupt 0 wake-up.
  [1] DMA — DMA wake-up.
  [0] WDT_BOD — WWDT and BOD interrupt wake-up.
0x684 STARTER1 — Start logic 0 wake-up enable register
  [16] USB1_ACT — USB 1 activity wake-up.
  [15] USB1 — USB 1 wake-up.
  [9] FLEXCOMM9 — Flexcomm Interface 9 wake-up.
  [8] FLEXCOMM8 — Flexcomm Interface 8 wake-up.
  [n-4] PINT{n} (n=4..7) — GPIO pin interrupt {n} wake-up.
{0x6A0+4i} STARTERSET[{i}] (i=0..1) wo — Set bits in STARTER
  [31:0] START_SET — Writing ones to this register sets the corresponding bit or bits in the STARTER0 register, if they are implemented.
{0x6C0+4i} STARTERCLR[{i}] (i=0..1) wo — Clear bits in STARTER0
  [31:0] START_CLR — Writing ones to this register clears the corresponding bit or bits in the STARTER0 register, if they are implemented.
0x780 HWWAKE — Configures special cases of hardware wake-up
  [3] WAKEDMA — Wake for DMA. When 1, DMA being busy will cause peripheral clocking to remain running until DMA completes. This is generally used in conjunction with bit 1 and/or 2 in order to prevent peripheral clocking from being shut down as soon as the cause of wake-up is cleared, but before DMA has completed its related activity.
  [2] WAKEDMIC — Wake for Digital Microphone. When 1, the digital microphone input FIFO reaching the level specified by TRIGLVL of either channel will cause peripheral clocking to wake up temporarily while the related status is asserted.
  [1] FCWAKE — Wake for Flexcomms. When 1, any Flexcomm FIFO reaching the level specified by its own TXLVL will cause peripheral clocking to wake up temporarily while the related status is asserted.
  [0] FORCEWAKE — Force peripheral clocking to stay on during Deep Sleep and Power-down modes. When 1, clocking to peripherals is prevented from being shut down when the CPU enters Deep Sleep and Power-down modes. This is intended to allow a coprocessor to continue operating while the main CPU(s) are shut down.
0xE04 AUTOCGOR (reset mask 0xE) — Auto Clock-Gate Override Register
  [4] RAM3 — When 1, automatic clock gating for RAM1 are turned off.
  [3] RAM2 — When 1, automatic clock gating for RAM1 are turned off.
  [2] RAM1 — When 1, automatic clock gating for RAM1 are turned off.
  [1] RAM0X — When 1, automatic clock gating for RAMX and RAM0 are turned off.
0xFF4 JTAGIDCODE ro
  [31:0] JTAGID — JTAG ID code.
0xFF8 DEVICE_ID0 ro — Part ID register
  [31:0] PARTID
0xFFC DEVICE_ID1 ro — Boot ROM and die revision register
  [31:0] REVID — Revision.

## Notices in the file
Redistribution and use in source and binary forms, with or without modification,
are permitted provided that the following conditions are met:
1. Redistributions of source code must retain the above copyright notice, this list
of conditions and the following disclaimer.
2. Redistributions in binary form must reproduce the above copyright notice, this
list of conditions and the following disclaimer in the documentation and/or
other materials provided with the distribution.
3. Neither the name of the copyright holder nor the names of its
contributors may be used to endorse or promote products derived from this
software without specific prior written permission.
THIS SOFTWARE IS PROVIDED BY THE COPYRIGHT HOLDERS AND CONTRIBUTORS "AS IS" AND
ANY EXPRESS OR IMPLIED WARRANTIES, INCLUDING, BUT NOT LIMITED TO, THE IMPLIED
WARRANTIES OF MERCHANTABILITY AND FITNESS FOR A PARTICULAR PURPOSE ARE
DISCLAIMED. IN NO EVENT SHALL THE COPYRIGHT HOLDER OR CONTRIBUTORS BE LIABLE FOR
ANY DIRECT, INDIRECT, INCIDENTAL, SPECIAL, EXEMPLARY, OR CONSEQUENTIAL DAMAGES
(INCLUDING, BUT NOT LIMITED TO, PROCUREMENT OF SUBSTITUTE GOODS OR SERVICES;
LOSS OF USE, DATA, OR PROFITS; OR BUSINESS INTERRUPTION) HOWEVER CAUSED AND ON
ANY THEORY OF LIABILITY, WHETHER IN CONTRACT, STRICT LIABILITY, OR TORT
(INCLUDING NEGLIGENCE OR OTHERWISE) ARISING IN ANY WAY OUT OF THE USE OF THIS
SOFTWARE, EVEN IF ADVISED OF THE POSSIBILITY OF SUCH DAMAGE.
